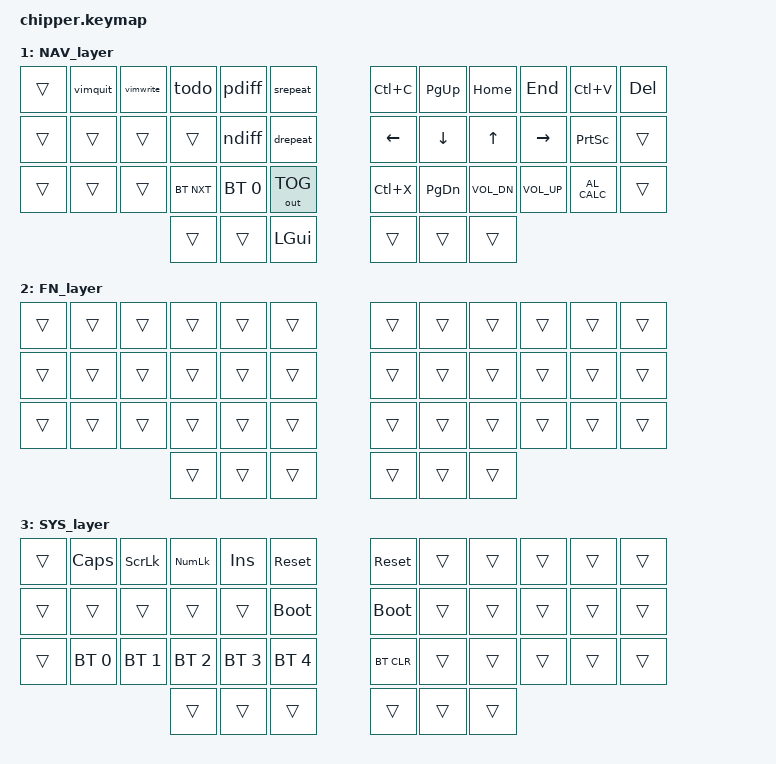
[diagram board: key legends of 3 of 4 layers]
#include <behaviors.dtsi>
#include <dt-bindings/zmk/keys.h>
#include <dt-bindings/zmk/bt.h>
#include <dt-bindings/zmk/outputs.h>

/* map 6 extra keys */
#define X_LT  &mt LS(LC(LALT)) ESC
#define X_LM  &mt RS(RC(RA(RGUI))) TAB
#define X_LB  &kp GLOBE
#define X_RT  &mt RS(RC(RA(RGUI))) DEL
#define X_RM  &kp RALT
#define X_RB  &kp RCTRL

#define XXX &none
#define ___ &trans

#define COMBO_TIMEOUT 60

#define DEF 0
#define NAV 1
#define FN 2
#define SYS 3

#include "combos.dtsi"
#include "macros.dtsi"

/ {
    macros {
	nayeon: nayeon {
            compatible = "zmk,behavior-macro";
            #binding-cells = <0>;
            bindings
                = <&macro_tap_time 10>
		,<&macro_tap &kp N &kp A &kp Y &kp E &kp O &kp N>
        ;
        };
    };
};
/ {
    conditional_layers {
        compatible = "zmk,conditional-layers";
        tri_layer {
            if-layers = <NAV FN>;
            then-layer = <SYS>;
        };
    };
};

/ {
    keymap {
        compatible = "zmk,keymap";

        DEF_layer {
            bindings = <
//╭──────╮  ╭─────────────┬─────────────┬─────────────┬─────────────┬─────────────╮ ╭──────╮ ╭─────────────┬─────────────┬─────────────┬─────────────┬─────────────╮ ╭──────╮
&kp TAB       &kp Q         &kp W         &kp E         &kp R         &kp T                    &kp Y         &kp U         &kp I         &kp O         &kp P           &kp BSPC
//├──────┤  ├─────────────┼─────────────┼─────────────┼─────────────┼─────────────┤ ├──────┤ ├─────────────┼─────────────┼─────────────┼─────────────┼─────────────┤ ├──────┤
&kp ESC       &kp A         &kp S         &kp D         &kp F         &kp G                    &kp H         &kp J         &kp K         &kp L         &kp SEMI        &kp ENTER
//├──────┤  ├─────────────┼─────────────┼─────────────┼─────────────┼─────────────┤ ├──────┤ ├─────────────┼─────────────┼─────────────┼─────────────┼─────────────┤ ├──────┤
&kp LSHFT     &kp Z         &kp X         &kp C         &kp V         &kp B                    &kp N         &kp M         &kp COMMA     &kp DOT       &kp FSLH        &kp RSHFT
//╰──────╯  ╰─────────────┼─────────────┴─────────────┼─────────────┼─────────────┤ ├──────┤ ├─────────────┼─────────────┼─────────────┴───────────────────────────╯ ╰──────╯
                                          &kp LALT      &kp LSHFT     &kp LCTRL                &kp LGUI      &lt NAV SPC   &lt FN XXX
//                                      ╰─────────────┼─────────────┴─────────────╯ ╰──────╯ ╰─────────────┴─────────────┼─────────────╯
            >;
        };

        NAV_layer {

            bindings = <
//╭──────╮  ╭─────────────┬─────────────┬─────────────┬─────────────┬─────────────╮ ╭──────╮ ╭─────────────┬─────────────┬─────────────┬─────────────┬─────────────╮ ╭──────╮
    ___       &vimquit      &vimwrite     &todo         &pdiff        &srepeat                 &kp LC(C)     &kp PG_UP     &kp HOME      &kp END        &kp LC(V)      &kp DEL
//├──────┤  ├─────────────┼─────────────┼─────────────┼─────────────┼─────────────┤ ├──────┤ ├─────────────┼─────────────┼─────────────┼─────────────┼─────────────┤ ├──────┤
    ___       ___           ___           ___           &ndiff        &drepeat                 &kp LEFT      &kp DOWN      &kp UP        &kp RIGHT      &kp PSCRN      ___
//├──────┤  ├─────────────┼─────────────┼─────────────┼─────────────┼─────────────┤ ├──────┤ ├─────────────┼─────────────┼─────────────┼─────────────┼─────────────┤ ├──────┤
    ___       ___           ___           &bt BT_NXT    &bt BT_SEL 0  &out OUT_TOG             &kp LC(X)     &kp PG_DN     &kp C_VOL_DN  &kp C_VOL_UP   &kp C_AL_CALC  ___
//╰──────╯  ╰─────────────┼─────────────┴─────────────┼─────────────┼─────────────┤ ├──────┤ ├─────────────┼─────────────┼─────────────┴───────────────────────────╯ ╰──────╯
                                          ___           ___           &kp LGUI                 ___           ___           ___
//                                      ╰─────────────┼─────────────┴─────────────╯ ╰──────╯ ╰─────────────┴─────────────┼─────────────╯
            >;
        };

        FN_layer {

            bindings = <
//╭──────╮  ╭─────────────┬─────────────┬─────────────┬─────────────┬─────────────╮ ╭──────╮ ╭─────────────┬─────────────┬─────────────┬─────────────┬─────────────╮ ╭──────╮
    ___       ___           ___           ___           ___           ___                      ___           ___           ___            ___          ___             ___
//├──────┤  ├─────────────┼─────────────┼─────────────┼─────────────┼─────────────┤ ├──────┤ ├─────────────┼─────────────┼─────────────┼─────────────┼─────────────┤ ├──────┤
    ___       ___           ___           ___           ___           ___                      ___           ___           ___            ___          ___             ___
//├──────┤  ├─────────────┼─────────────┼─────────────┼─────────────┼─────────────┤ ├──────┤ ├─────────────┼─────────────┼─────────────┼─────────────┼─────────────┤ ├──────┤
    ___       ___           ___           ___           ___           ___                      ___           ___           ___            ___          ___             ___
//╰──────╯  ╰─────────────┼─────────────┴─────────────┼─────────────┼─────────────┤ ├──────┤ ├─────────────┼─────────────┼─────────────┴───────────────────────────╯ ╰──────╯
                                          ___           ___           ___                      ___           ___           ___
//                                      ╰─────────────┼─────────────┴─────────────╯ ╰──────╯ ╰─────────────┴─────────────┼─────────────╯
            >;
        };

        SYS_layer {

            bindings = <
//╭──────╮  ╭─────────────┬─────────────┬─────────────┬─────────────┬─────────────╮ ╭──────╮ ╭─────────────┬─────────────┬─────────────┬─────────────┬─────────────╮ ╭──────╮
    ___       &kp CAPS      &kp SLCK      &kp KP_NLCK   &kp INS       &sys_reset               &sys_reset    ___           ___           ___           ___             ___
//├──────┤  ├─────────────┼─────────────┼─────────────┼─────────────┼─────────────┤ ├──────┤ ├─────────────┼─────────────┼─────────────┼─────────────┼─────────────┤ ├──────┤
    ___       ___           ___           ___           ___           &bootloader              &bootloader   ___           ___           ___           ___             ___
//├──────┤  ├─────────────┼─────────────┼─────────────┼─────────────┼─────────────┤ ├──────┤ ├─────────────┼─────────────┼─────────────┼─────────────┼─────────────┤ ├──────┤
    ___       &bt BT_SEL 0  &bt BT_SEL 1  &bt BT_SEL 2  &bt BT_SEL 3  &bt BT_SEL 4             &bt BT_CLR    ___           ___           ___           ___             ___
//╰──────╯  ╰─────────────┼─────────────┴─────────────┼─────────────┼─────────────┤ ├──────┤ ├─────────────┼─────────────┼─────────────┴───────────────────────────╯ ╰──────╯
                                          ___           ___           ___                      ___           ___           ___
//                                      ╰─────────────┼─────────────┴─────────────╯ ╰──────╯ ╰─────────────┴─────────────┼─────────────╯
            >;
        };
    };
};
